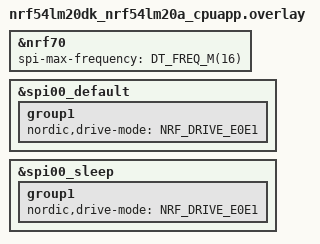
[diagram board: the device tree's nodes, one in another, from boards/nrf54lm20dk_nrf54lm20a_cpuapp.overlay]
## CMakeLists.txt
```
#
# Copyright (c) 2026 Nordic Semiconductor ASA
#
# SPDX-License-Identifier: LicenseRef-Nordic-5-Clause
#

cmake_minimum_required(VERSION 3.20.0)

find_package(Zephyr REQUIRED HINTS $ENV{ZEPHYR_BASE})
project(nordic_wifi_softap_webserver)

target_include_directories(app PUBLIC ${ZEPHYR_BASE}/subsys/net/ip)

# Linker script additions for HTTP resources
zephyr_linker_sources(SECTIONS sections-rom.ld)

# Add http service
zephyr_linker_section_ifdef(CONFIG_HTTP_SERVER NAME
				http_resource_desc_webserver_service
				KVMA RAM_REGION GROUP RODATA_REGION
				SUBALIGN Z_LINK_ITERABLE_SUBALIGN)

# Add static web resources
set(gen_dir ${ZEPHYR_BINARY_DIR}/include/generated/)

foreach(web_resource
  index.html
  main.js
  styles.css
    )
  generate_inc_file_for_target(
    app
    www/${web_resource}
    ${gen_dir}/${web_resource}.gz.inc
    --gzip
  )
endforeach()

# Add subdirectories for modules
add_subdirectory(src/modules/network)
add_subdirectory(src/modules/button)
add_subdirectory(src/modules/led)
add_subdirectory(src/modules/wifi)
add_subdirectory(src/modules/webserver)
add_subdirectory(src/modules/memory)

target_sources(app PRIVATE
	src/main.c
)
```

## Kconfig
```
#
# Copyright (c) 2026 Nordic Semiconductor ASA
#
# SPDX-License-Identifier: LicenseRef-Nordic-5-Clause
#

menu "Nordic WiFi SoftAP Webserver"

config APP_WIFI_SSID
	string "WiFi SoftAP SSID"
	default "nRF70-WebServer"
	help
	  SSID of the WiFi SoftAP to create. Override this value in
	  overlay-wifi-credentials.conf (listed in .gitignore) to avoid committing
	  production credentials.

config APP_WIFI_PASSWORD
	string "WiFi SoftAP Password"
	default "12345678"
	help
	  Password for WiFi SoftAP (min 8 characters for WPA2). Provide real
	  credentials via the local overlay-wifi-credentials.conf to keep secrets
	  out of version control.

config APP_HTTP_PORT
	int "HTTP Server Port"
	default 80
	help
	  HTTP server port number

rsource "src/modules/network/Kconfig.network"
rsource "src/modules/button/Kconfig.button"
rsource "src/modules/led/Kconfig.led"
rsource "src/modules/wifi/Kconfig.wifi"
rsource "src/modules/webserver/Kconfig.webserver"
rsource "src/modules/memory/Kconfig.memory"

endmenu

source "Kconfig.zephyr"
```

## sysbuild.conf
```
#
# Copyright (c) 2026 Nordic Semiconductor ASA
#
# SPDX-License-Identifier: LicenseRef-Nordic-5-Clause
#

# WiFi support
SB_CONFIG_WIFI_NRF70=y

# Network core image configuration for nRF5340
# Use empty network core image by default
SB_CONFIG_NETCORE_NONE=y
```

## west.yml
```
manifest:
  version: 0.13
  defaults:
    remote: ncs
  remotes:
    - name: ncs
      url-base: https://github.com/nrfconnect
  projects:
    - name: sdk-nrf
      path: nrf
      revision: v3.2.1
      import: true
      remote: ncs
  self:
    path: nordic_wifi_softap_webserver
```

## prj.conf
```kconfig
#
# Copyright (c) 2026 Nordic Semiconductor ASA
#
# SPDX-License-Identifier: LicenseRef-Nordic-5-Clause
#

# WiFi Configuration
CONFIG_WIFI=y
CONFIG_WIFI_NRF70=y

# WPA supplicant
CONFIG_WIFI_NM_WPA_SUPPLICANT=y
CONFIG_WIFI_NM_WPA_SUPPLICANT_AP=y
CONFIG_WIFI_NM_WPA_SUPPLICANT_THREAD_STACK_SIZE=8192

# nRF70 SoftAP mode
CONFIG_NRF70_AP_MODE=y
CONFIG_NRF_WIFI_LOW_POWER=n

# Shell
CONFIG_SHELL=n
CONFIG_NET_L2_WIFI_SHELL=n
CONFIG_WIFI_SHELL_MAX_AP_STA=2

# Networking
CONFIG_NETWORKING=y
CONFIG_NET_SOCKETS=y
CONFIG_NET_IPV4=y
CONFIG_NET_UDP=y
CONFIG_NET_TCP=y
CONFIG_NET_IPV6=n

# DHCP Server for SoftAP
CONFIG_NET_DHCPV4=y
CONFIG_NET_DHCPV4_SERVER=y
CONFIG_NET_DHCPV4_SERVER_ADDR_COUNT=2

# Static IP configuration for SoftAP
CONFIG_NET_CONFIG_SETTINGS=y
CONFIG_NET_CONFIG_MY_IPV4_ADDR="192.168.7.1"
CONFIG_NET_CONFIG_MY_IPV4_NETMASK="255.255.255.0"
CONFIG_NET_CONFIG_MY_IPV4_GW="192.168.7.1"
CONFIG_NET_CONFIG_INIT_TIMEOUT=0

# Network buffers - tuned for performance
CONFIG_NET_PKT_RX_COUNT=16
CONFIG_NET_PKT_TX_COUNT=24
CONFIG_NET_BUF_RX_COUNT=16
CONFIG_NET_BUF_TX_COUNT=32
CONFIG_NRF70_RX_NUM_BUFS=16
# CONFIG_NET_BUF_DATA_SIZE requires CONFIG_NET_BUF_FIXED_DATA_SIZE to be enabled
# Using default buffer size instead (works well for this application)
# CONFIG_NET_BUF_DATA_SIZE=1100
CONFIG_NET_TC_TX_COUNT=1

CONFIG_NET_IF_UNICAST_IPV4_ADDR_COUNT=1
CONFIG_NET_MAX_CONTEXTS=16
CONFIG_NET_MAX_CONN=16
CONFIG_NET_CONTEXT_SYNC_RECV=y
CONFIG_NET_CONTEXT_RCVTIMEO=y

CONFIG_NET_L2_ETHERNET=y
CONFIG_NET_SOCKETS_POLL_MAX=10

# HTTP Server
CONFIG_HTTP_PARSER_URL=y
CONFIG_HTTP_PARSER=y
CONFIG_HTTP_SERVER=y
CONFIG_HTTP_SERVER_MAX_CLIENTS=10
CONFIG_HTTP_SERVER_MAX_STREAMS=10
# CONFIG_NET_LOG=y
# CONFIG_NET_HTTP_SERVER_LOG_LEVEL_DBG=y
# CONFIG_HTTP_SERVER_REPORT_FAILURE_REASON=y

# mDNS/DNS-SD - Enables .local hostname access
CONFIG_MDNS_RESPONDER=y
CONFIG_DNS_SD=y
CONFIG_MDNS_RESPONDER_DNS_SD=y
CONFIG_NET_HOSTNAME_ENABLE=y
CONFIG_NET_HOSTNAME_UNIQUE=n
CONFIG_NET_HOSTNAME="nrfwifi"

# DNS Resolver - Required for mDNS to work properly
CONFIG_DNS_RESOLVER=y
CONFIG_DNS_RESOLVER_AUTO_INIT=y

# SMF (State Machine Framework)
CONFIG_SMF=y
CONFIG_SMF_INITIAL_TRANSITION=y
CONFIG_SMF_ANCESTOR_SUPPORT=y

# Zbus (Message Bus)
CONFIG_ZBUS=y
CONFIG_ZBUS_PRIORITY_BOOST=y
CONFIG_ZBUS_RUNTIME_OBSERVERS=y
CONFIG_ZBUS_MSG_SUBSCRIBER=y

# GPIO for buttons and LEDs
CONFIG_GPIO=y
CONFIG_DK_LIBRARY=y

# JSON
CONFIG_JSON_LIBRARY=y

# Memory configuration (sized from thread analyzer high-water marks)
CONFIG_MAIN_STACK_SIZE=2048
CONFIG_SHELL_STACK_SIZE=2048
CONFIG_NET_RX_STACK_SIZE=2048
CONFIG_NET_TX_STACK_SIZE=2048
CONFIG_SYSTEM_WORKQUEUE_STACK_SIZE=2048
CONFIG_NET_MGMT_EVENT_STACK_SIZE=2048
CONFIG_HTTP_SERVER_STACK_SIZE=2048
CONFIG_WIFI_NM_WPA_SUPPLICANT_THREAD_STACK_SIZE=8192
CONFIG_WIFI_NM_WPA_SUPPLICANT_WQ_STACK_SIZE=5632
CONFIG_NET_SOCKETS_SERVICE_STACK_SIZE=3072

# Debugging
CONFIG_STACK_SENTINEL=y
CONFIG_DEBUG_COREDUMP=y
CONFIG_DEBUG_COREDUMP_BACKEND_LOGGING=y
CONFIG_DEBUG_COREDUMP_MEMORY_DUMP_MIN=y
CONFIG_SHELL_CMDS_RESIZE=n

# Kernel options
CONFIG_ENTROPY_GENERATOR=y
CONFIG_INIT_STACKS=y

# Logging
CONFIG_LOG=y
CONFIG_LOG_BUFFER_SIZE=2048
CONFIG_LOG_MODE_DEFERRED=y

# Eventfd - Increased for WPA supplicant (needs more than 2)
CONFIG_EVENTFD=y
CONFIG_ZVFS_OPEN_MAX=48
CONFIG_ZVFS_EVENTFD_MAX=16
CONFIG_POSIX_API=y
CONFIG_FDTABLE=y

# Debug Logging
CONFIG_BUTTON_MODULE_LOG_LEVEL_INF=y
CONFIG_LED_MODULE_LOG_LEVEL_INF=y
CONFIG_WIFI_MODULE_LOG_LEVEL_INF=y
CONFIG_WEBSERVER_MODULE_LOG_LEVEL_INF=y


# Memory & heap tuning
# WPA supplicant and POSIX subsystems already add ~46 KB through
# HEAP_MEM_POOL_ADD_SIZE_* (hostap + sockets + Zbus). Keep the base heap at 80 KB
# so the total managed heap stays around 125 KB while leaving measurable headroom.
CONFIG_HEAP_MEM_POOL_SIZE=50000
CONFIG_HEAP_MEM_POOL_IGNORE_MIN=n
CONFIG_NRF_WIFI_GLOBAL_HEAP=n

# Thread Optimizations
# CONFIG_THREAD_ANALYZER=y
# CONFIG_DEBUG_THREAD_INFO=y
# CONFIG_THREAD_ANALYZER_USE_LOG=y
# CONFIG_THREAD_ANALYZER_AUTO=y
# CONFIG_THREAD_ANALYZER_AUTO_INTERVAL=10

# Heap Optimizations
CONFIG_MINIMAL_LIBC=n
CONFIG_PICOLIBC=y
CONFIG_NEWLIB_LIBC=n
# CONFIG_SYS_HEAP_LISTENER=y
# CONFIG_SYS_HEAP_RUNTIME_STATS=y
# CONFIG_APP_HEAP_MONITOR=y
# CONFIG_APP_HEAP_MONITOR_WARN_PCT=88
# CONFIG_APP_HEAP_MONITOR_STEP_BYTES=256
```

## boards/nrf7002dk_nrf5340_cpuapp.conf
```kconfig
#
# Copyright (c) 2026 Nordic Semiconductor ASA
#
# SPDX-License-Identifier: LicenseRef-Nordic-5-Clause
#

# Board-specific configuration for nRF7002DK

# Enable nRF70 series WiFi
CONFIG_WIFI=y
CONFIG_WIFI_NRF70=y

# Board has 4 LEDs and 4 buttons
CONFIG_DK_LIBRARY=y

# Optimize for nRF5340
CONFIG_FPU=y
```

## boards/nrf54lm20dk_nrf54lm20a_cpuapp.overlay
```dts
/*
 * SPDX-License-Identifier: LicenseRef-Nordic-5-Clause
 */

#include <freq.h>
#include <zephyr/dt-bindings/pinctrl/nrf-pinctrl.h>


&nrf70 {
	spi-max-frequency = <DT_FREQ_M(16)>;
};

&spi00_default {
	group1 {
		nordic,drive-mode = <NRF_DRIVE_E0E1>;
	};
};

&spi00_sleep {
	group1 {
		nordic,drive-mode = <NRF_DRIVE_E0E1>;
	};
};
```

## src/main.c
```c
/*
 * Copyright (c) 2026 Nordic Semiconductor ASA
 *
 * SPDX-License-Identifier: LicenseRef-Nordic-5-Clause
 */

#include <zephyr/logging/log.h>
LOG_MODULE_REGISTER(main, CONFIG_LOG_DEFAULT_LEVEL);

#include <zephyr/kernel.h>
#include <zephyr/zbus/zbus.h>
#include <zephyr/net/net_if.h>
#include <string.h>

#include "modules/button/button.h"
#include "modules/led/led.h"
#include "modules/messages.h"
#include "modules/webserver/webserver.h"
#include "modules/wifi/wifi.h"

/* ============================================================================
 * APPLICATION STATE MONITORING
 * ============================================================================
 */

/* Subscribe to WiFi events to start webserver when WiFi is ready */
static void wifi_event_listener(const struct zbus_channel *chan)
{
	const struct wifi_msg *msg = zbus_chan_const_msg(chan);

	if (msg->type == WIFI_SOFTAP_STARTED) {
		LOG_INF("WiFi SoftAP started, starting webserver...");

		/* Small delay to ensure network is fully configured */
		k_sleep(K_SECONDS(2));

		int ret = webserver_start();
		if (ret < 0) {
			LOG_ERR("Failed to start webserver: %d", ret);
		}
	}
}

ZBUS_LISTENER_DEFINE(wifi_event_listener_def, wifi_event_listener);

/* Extern reference to WiFi channel */
extern const struct zbus_channel WIFI_CHAN;
ZBUS_CHAN_ADD_OBS(WIFI_CHAN, wifi_event_listener_def, 0);

/* ============================================================================
 * MAIN APPLICATION
 * ============================================================================
 */

int main(void)
{
	struct net_if *iface = net_if_get_default();
	struct net_linkaddr *mac_addr = net_if_get_link_addr(iface);
	const char *board_name;

	/* Convert board name to proper case */
	if (strcmp(CONFIG_BOARD, "nrf7002dk") == 0 ||
	    strstr(CONFIG_BOARD, "nrf7002dk") != NULL) {
		board_name = "nRF7002DK";
	} else if (strcmp(CONFIG_BOARD, "nrf54lm20dk") == 0 ||
		   strstr(CONFIG_BOARD, "nrf54lm20dk") != NULL) {
		board_name = "nRF54LM20DK+nRF7002EBII";
	} else {
		board_name = CONFIG_BOARD;
	}

	LOG_INF("==============================================");
	LOG_INF("Nordic WiFi SoftAP Webserver");
	LOG_INF("==============================================");
	LOG_INF("Build: %s %s", __DATE__, __TIME__);
	LOG_INF("Board: %s", board_name);

	/* Print MAC address in the format "MAC: F4:CE:36:00:8B:E9" */
	if (mac_addr && mac_addr->len == 6) {
		LOG_INF("MAC: %02X:%02X:%02X:%02X:%02X:%02X", mac_addr->addr[0],
			mac_addr->addr[1], mac_addr->addr[2], mac_addr->addr[3],
			mac_addr->addr[4], mac_addr->addr[5]);
	}

	LOG_INF("==============================================");

	LOG_INF("All modules initialized via SYS_INIT");
	LOG_INF("WiFi SoftAP will start automatically");
	LOG_INF("Connect to WiFi SSID: %s", CONFIG_APP_WIFI_SSID);
	LOG_INF("Use password configured in overlay-wifi-credentials.conf.");
	LOG_INF("Or default WiFi Password 12345678 for SSID nRF70-WebServer.");
	LOG_INF("Then browse to: http://192.168.7.1:%d", CONFIG_APP_HTTP_PORT);
	LOG_INF("==============================================");

	/* Main thread can sleep forever - everything runs in module threads */
	while (1) {
		k_sleep(K_FOREVER);
	}

	return 0;
}
```
